AUTOSAR XML (schema 4-2-2)
package /ComponentTypes
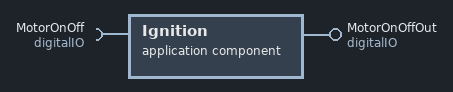
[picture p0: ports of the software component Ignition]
  application sw component type Ignition
    require port MotorOnOff: required-interface=digitalIO
    provide port MotorOnOffOut: provided-interface=digitalIO
    behavior Ignition_InternalBehavior
  swc implementation Ignition_Implementation: behavior=Ignition_InternalBehavior
